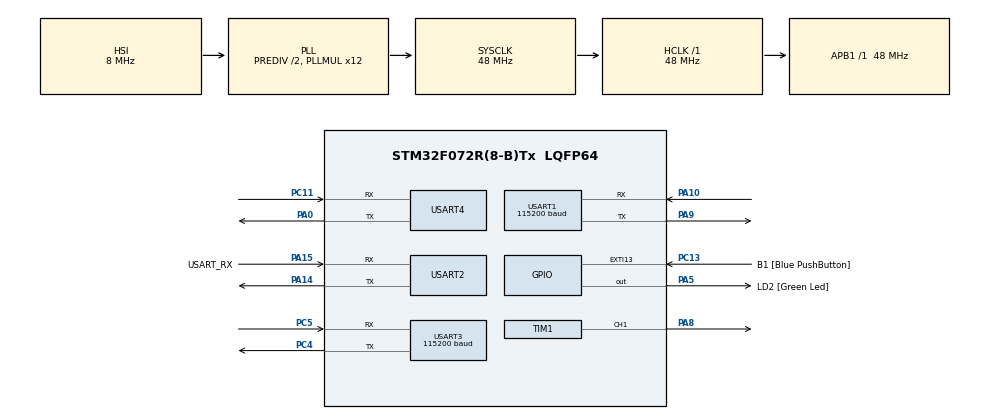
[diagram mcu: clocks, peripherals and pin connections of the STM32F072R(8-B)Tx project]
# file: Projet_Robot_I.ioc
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Mcu.Family=STM32F0
Mcu.Name=STM32F072R(8-B)Tx
Mcu.Package=LQFP64
NVIC.USART1_IRQn=true\:0\:0\:false\:false\:true\:true\:true
NVIC.USART3_4_IRQn=true\:0\:0\:false\:false\:true\:true\:true
PA0.Mode=Asynchronous
PA0.Signal=USART4_TX
PA10.Mode=Asynchronous
PA10.Signal=USART1_RX
PA13.GPIO_Label=TMS
PA13.Signal=SYS_SWDIO
PA14.Mode=Asynchronous
PA14.Signal=USART2_TX
PA15.GPIO_Label=USART_RX
PA15.GPIO_PuPd=GPIO_NOPULL
PA15.GPIO_Speed=GPIO_SPEED_FREQ_LOW
PA15.Mode=Asynchronous
PA15.Signal=USART2_RX
PA5.GPIO_Label=LD2 [Green Led]
PA5.GPIO_Mode=GPIO_MODE_OUTPUT_PP
PA5.GPIO_PuPd=GPIO_NOPULL
PA5.GPIO_Speed=GPIO_SPEED_FREQ_LOW
PA5.Signal=GPIO_Output
PA8.Signal=S_TIM1_CH1
PA9.Mode=Asynchronous
PA9.Signal=USART1_TX
PC11.Mode=Asynchronous
PC11.Signal=USART4_RX
PC13.GPIO_Label=B1 [Blue PushButton]
PC13.GPIO_ModeDefaultEXTI=GPIO_MODE_IT_FALLING
PC13.Signal=GPXTI13
PC14-OSC32_IN.Signal=RCC_OSC32_IN
PC15-OSC32_OUT.Signal=RCC_OSC32_OUT
PC4.Mode=Asynchronous
PC4.Signal=USART3_TX
PC5.Mode=Asynchronous
PC5.Signal=USART3_RX
PF0-OSC_IN.Signal=RCC_OSC_IN
PF1-OSC_OUT.Signal=RCC_OSC_OUT
ProjectManager.HeapSize=0x200
ProjectManager.StackSize=0x400
ProjectManager.TargetToolchain=STM32CubeIDE
RCC.AHBFreq_Value=48000000
RCC.APB1Freq_Value=48000000
RCC.APB1TimFreq_Value=48000000
RCC.FLatency-AdvancedSettings=FLASH_LATENCY_1
RCC.HCLKFreq_Value=48000000
RCC.PLLDivider=RCC_PREDIV_DIV2
RCC.PLLMUL=RCC_PLL_MUL12
RCC.SYSCLKFreq_VALUE=48000000
RCC.SYSCLKSource=RCC_SYSCLKSOURCE_PLLCLK
SH.S_TIM1_CH1.0=TIM1_CH1,Output Compare1 CH1
TIM1.Channel-Output\ Compare1\ CH1=TIM_CHANNEL_1
USART1.BaudRate=115200
USART1.VirtualMode-Asynchronous=VM_ASYNC
USART2.VirtualMode-Asynchronous=VM_ASYNC
USART3.BaudRate=115200
USART3.VirtualMode-Asynchronous=VM_ASYNC
USART4.VirtualMode-Asynchronous=VM_ASYNC
VP_TIM1_VS_ClockSourceITR.Mode=TriggerSource_ITR0
VP_TIM1_VS_ControllerModeClock.Mode=Clock Mode
board=NUCLEO-F072RB

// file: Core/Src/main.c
/* USER CODE BEGIN Header */
/**
  ******************************************************************************
  * @file           : main.c
  * @brief          : Main program body
  ******************************************************************************
  * @attention
  *
  * <h2><center>&copy; Copyright (c) 2021 STMicroelectronics.
  * All rights reserved.</center></h2>
  *
  * This software component is licensed by ST under BSD 3-Clause license,
  * the "License"; You may not use this file except in compliance with the
  * License. You may obtain a copy of the License at:
  *                        opensource.org/licenses/BSD-3-Clause
  *
  ******************************************************************************
  */
/* USER CODE END Header */
#include "main.h"
#include "tim.h"
#include "usart.h"
#include "gpio.h"

/* USER CODE BEGIN Includes */

#include "com_pc.h"

/* USER CODE END Includes */

/* USER CODE BEGIN PV */

uint16_t UART1_rxBuffer [10];
uint16_t UART2_rxBuffer [10];

uint16_t UART1_txBuffer [10];
uint16_t UART2_txBuffer [10];

/* USER CODE END PV */

void SystemClock_Config(void);

int main(void)
{

  /* MCU Configuration--------------------------------------------------------*/

  /* Reset of all peripherals, Initializes the Flash interface and the Systick. */
  HAL_Init();

  /* Configure the system clock */
  SystemClock_Config();

  /* Initialize all configured peripherals */
  MX_GPIO_Init();
  MX_USART1_UART_Init();
  MX_TIM1_Init();
  MX_USART3_UART_Init();
  MX_USART2_UART_Init();
  MX_USART4_UART_Init();
  /* USER CODE BEGIN 2 */

  HAL_UART_Receive_IT(&huart1, UART1_rxBuffer, sizeof(UART1_rxBuffer));
  HAL_UART_Receive_IT(&huart2, UART2_rxBuffer, sizeof(UART2_rxBuffer));
  HAL_UART_Receive_IT(&huart3, UART3_rxBuffer, sizeof(UART3_rxBuffer));
  HAL_UART_Receive_IT(&huart4, UART4_rxBuffer, sizeof(UART4_rxBuffer));

  /* USER CODE END 2 */

  /* Infinite loop */
  /* USER CODE BEGIN WHILE */
  while (1)
  {

	  char Data[] = "coucou";
	  HAL_UART_Transmit(&huart1, Data, 10, 100);
	  HAL_UART_Transmit(&huart3, Data, 10, 100);
	  HAL_Delay(100);

    /* USER CODE END WHILE */

  }
}

void SystemClock_Config(void)
{
  RCC_OscInitTypeDef RCC_OscInitStruct = {0};
  RCC_ClkInitTypeDef RCC_ClkInitStruct = {0};
  RCC_PeriphCLKInitTypeDef PeriphClkInit = {0};

  /** Initializes the RCC Oscillators according to the specified parameters
  * in the RCC_OscInitTypeDef structure.
  */
  RCC_OscInitStruct.OscillatorType = RCC_OSCILLATORTYPE_HSI;
  RCC_OscInitStruct.HSIState = RCC_HSI_ON;
  RCC_OscInitStruct.HSICalibrationValue = RCC_HSICALIBRATION_DEFAULT;
  RCC_OscInitStruct.PLL.PLLState = RCC_PLL_ON;
  RCC_OscInitStruct.PLL.PLLSource = RCC_PLLSOURCE_HSI;
  RCC_OscInitStruct.PLL.PLLMUL = RCC_PLL_MUL12;
  RCC_OscInitStruct.PLL.PREDIV = RCC_PREDIV_DIV2;
  if (HAL_RCC_OscConfig(&RCC_OscInitStruct) != HAL_OK)
  {
    Error_Handler();
  }
  /** Initializes the CPU, AHB and APB buses clocks
  */
  RCC_ClkInitStruct.ClockType = RCC_CLOCKTYPE_HCLK|RCC_CLOCKTYPE_SYSCLK
                              |RCC_CLOCKTYPE_PCLK1;
  RCC_ClkInitStruct.SYSCLKSource = RCC_SYSCLKSOURCE_PLLCLK;
  RCC_ClkInitStruct.AHBCLKDivider = RCC_SYSCLK_DIV1;
  RCC_ClkInitStruct.APB1CLKDivider = RCC_HCLK_DIV1;

  if (HAL_RCC_ClockConfig(&RCC_ClkInitStruct, FLASH_LATENCY_1) != HAL_OK)
  {
    Error_Handler();
  }
  PeriphClkInit.PeriphClockSelection = RCC_PERIPHCLK_USART1|RCC_PERIPHCLK_USART2;
  PeriphClkInit.Usart1ClockSelection = RCC_USART1CLKSOURCE_PCLK1;
  PeriphClkInit.Usart2ClockSelection = RCC_USART2CLKSOURCE_PCLK1;
  if (HAL_RCCEx_PeriphCLKConfig(&PeriphClkInit) != HAL_OK)
  {
    Error_Handler();
  }
}

void Error_Handler(void)
{
  __disable_irq();
  while (1)
  {
  }
}

/************************ (C) COPYRIGHT STMicroelectronics *****END OF FILE****/
